# ATSAME51J18A device description
Architecture: CORTEX-M4; Family: SAME; Series: SAME51
Registers are 32-bit, read-write, reset 0x0 unless marked. A register's access mark holds for its fields unless they carry their own. Offsets are from the block's base; [hi:lo] are bit positions; {n}, {i} and the like mark numbered series; 'fields as' and 'values as' point back to an identical list.

## AES — Advanced Encryption Standard
Instances: AES 0x42002400
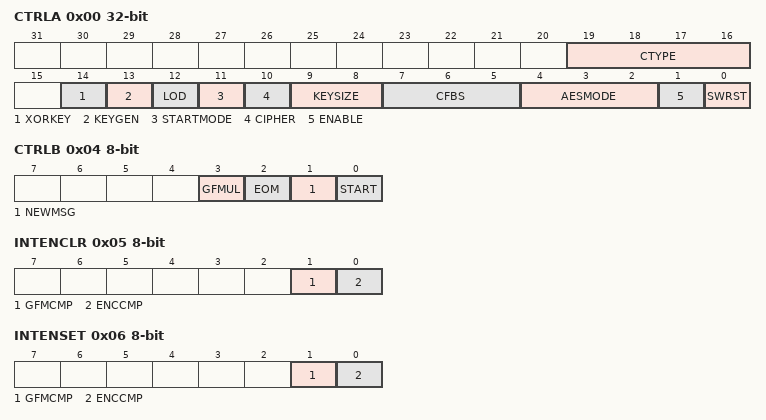
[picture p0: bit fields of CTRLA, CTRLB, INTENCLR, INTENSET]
0x00 CTRLA — Control A
  [19:16] CTYPE — Counter Measure Type
  [14] XORKEY — XOR Key Operation
    0=NONE (No effect); 1=XOR (The user keyword gets XORed with the previous keyword register content.)
  [13] KEYGEN — Last Key Generation
    0=NONE (No effect); 1=LAST (Start Computation of the last NK words of the expanded key)
  [12] LOD — Last Output Data Mode
    0=NONE (No effect); 1=LAST (Start encryption in Last Output Data mode)
  [11] STARTMODE — Start Mode Select
    0=MANUAL (Start Encryption / Decryption in Manual mode); 1=AUTO (Start Encryption / Decryption in Auto mode)
  [10] CIPHER — Cipher Mode
    0=DEC (Decryption); 1=ENC (Encryption)
  [9:8] KEYSIZE — Encryption Key Size
    0=128BIT (128-bit Key for Encryption / Decryption); 1=192BIT (192-bit Key for Encryption / Decryption); 2=256BIT (256-bit Key for Encryption / Decryption)
  [7:5] CFBS — Cipher Feedback Block Size
    0=128BIT (128-bit Input data block for Encryption/Decryption in Cipher Feedback mode); 1=64BIT (64-bit Input data block for Encryption/Decryption in Cipher Feedback mode); 2=32BIT (32-bit Input data block for Encryption/Decryption in Cipher Feedback mode); 3=16BIT (16-bit Input data block for Encryption/Decryption in Cipher Feedback mode); 4=8BIT (8-bit Input data block for Encryption/Decryption in Cipher Feedback mode)
  [4:2] AESMODE — AES Modes of operation
    0=ECB (Electronic code book mode); 1=CBC (Cipher block chaining mode); 2=OFB (Output feedback mode); 3=CFB (Cipher feedback mode); 4=COUNTER (Counter mode); 5=CCM (CCM mode); 6=GCM (Galois counter mode)
  [1] ENABLE
  [0] SWRST — Software Reset
0x04 CTRLB 8-bit — Control B
  [3] GFMUL — GF Multiplication
  [2] EOM — End of message
  [1] NEWMSG — New message
  [0] START — Start Encryption/Decryption
0x05 INTENCLR 8-bit (atomic clear) — Interrupt Enable Clear
  [1] GFMCMP — GF Multiplication Complete Interrupt Enable
  [0] ENCCMP — Encryption Complete Interrupt Enable
0x06 INTENSET 8-bit (atomic set) — Interrupt Enable Set
  fields as INTENCLR
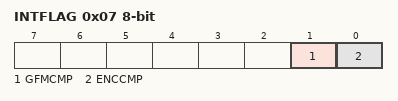
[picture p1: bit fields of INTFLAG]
0x07 INTFLAG 8-bit (atomic clear) — Interrupt Flag Status
  [1] GFMCMP — GF Multiplication Complete
  [0] ENCCMP — Encryption Complete
0x08 DATABUFPTR 8-bit — Data buffer pointer
  [1:0] INDATAPTR — Input Data Pointer
0x09 DBGCTRL 8-bit — Debug control
  [0] DBGRUN — Debug Run
{0xC+4i} KEYWORD[{i}] (i=0..7) wo — Keyword n
0x38 INDATA
{0x3C+4i} INTVECTV[{i}] (i=0..3) wo — Initialisation Vector n
{0x5C+4i} HASHKEY[{i}] (i=0..3) — Hash key n
{0x6C+4i} GHASH[{i}] (i=0..3) — Galois Hash n
0x80 CIPLEN — Cipher Length
0x84 RANDSEED — Random Seed

## CAN_RXBE — Rx Buffer Element
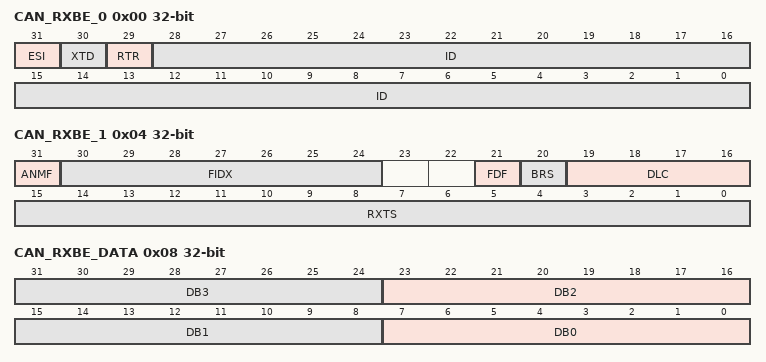
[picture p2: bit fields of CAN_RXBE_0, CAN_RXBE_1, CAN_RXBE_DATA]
0x00 CAN_RXBE_0 reset not defined — Rx Buffer Element 0
  [31] ESI — Error State Indicator
  [30] XTD — Extended Identifier
  [29] RTR — Remote Transmission Request
  [28:0] ID — Identifier
0x04 CAN_RXBE_1 reset not defined — Rx Buffer Element 1
  [31] ANMF — Accepted Non-matching Frame
  [30:24] FIDX — Filter Index
  [21] FDF — FD Format
  [20] BRS — Bit Rate Switch
  [19:16] DLC — Data Length Code
  [15:0] RXTS — Rx Timestamp
0x08 CAN_RXBE_DATA reset not defined — Rx Buffer Element Data
  [8n+7:8n] DB{n} (n=0..3) — Data Byte {n}

## CAN_RXF0E — Rx FIFO 0 Element
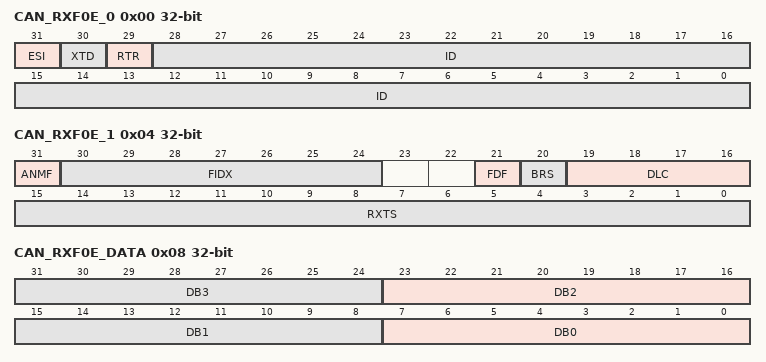
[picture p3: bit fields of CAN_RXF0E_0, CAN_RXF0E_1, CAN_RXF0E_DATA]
0x00 CAN_RXF0E_0 reset not defined — Rx FIFO 0 Element 0
  [31] ESI — Error State Indicator
  [30] XTD — Extended Identifier
  [29] RTR — Remote Transmission Request
  [28:0] ID — Identifier
0x04 CAN_RXF0E_1 reset not defined — Rx FIFO 0 Element 1
  [31] ANMF — Accepted Non-matching Frame
  [30:24] FIDX — Filter Index
  [21] FDF — FD Format
  [20] BRS — Bit Rate Switch
  [19:16] DLC — Data Length Code
  [15:0] RXTS — Rx Timestamp
0x08 CAN_RXF0E_DATA reset not defined — Rx FIFO 0 Element Data
  [8n+7:8n] DB{n} (n=0..3) — Data Byte {n}

## Notices in the file
Copyright (c) 2018 Microchip Technology Inc.
SPDX-License-Identifier: Apache-2.0
Licensed under the Apache License, Version 2.0 (the "License");
you may not use this file except in compliance with the License.
You may obtain a copy of the License at
http://www.apache.org/licenses/LICENSE-2.0
Unless required by applicable law or agreed to in writing, software
distributed under the License is distributed on an "AS IS" BASIS,
WITHOUT WARRANTIES OR CONDITIONS OF ANY KIND, either express or implied.
See the License for the specific language governing permissions and
limitations under the License.
